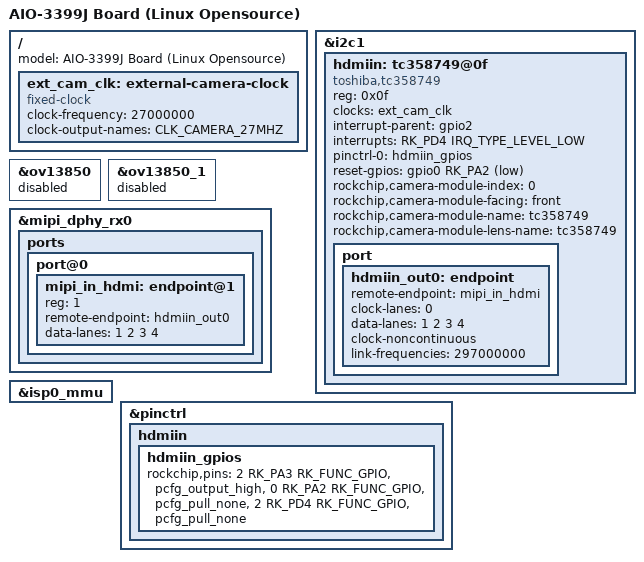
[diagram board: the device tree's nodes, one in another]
/*
 * Copyright (c) 2016 Fuzhou Rockchip Electronics Co., Ltd
 *
 * This file is dual-licensed: you can use it either under the terms
 * of the GPL or the X11 license, at your option. Note that this dual
 * licensing only applies to this file, and not this project as a
 * whole.
 *
 *  a) This file is free software; you can redistribute it and/or
 *     modify it under the terms of the GNU General Public License as
 *     published by the Free Software Foundation; either version 2 of the
 *     License, or (at your option) any later version.
 *
 *     This file is distributed in the hope that it will be useful,
 *     but WITHOUT ANY WARRANTY; without even the implied warranty of
 *     MERCHANTABILITY or FITNESS FOR A PARTICULAR PURPOSE.  See the
 *     GNU General Public License for more details.
 *
 * Or, alternatively,
 *     restriction, including without limitation the rights to use,
 *     copy, modify, merge, publish, distribute, sublicense, and/or
 *     sell copies of the Software, and to permit persons to whom the
 *     Software is furnished to do so, subject to the following
 *     conditions:
 *
 *     The above copyright notice and this permission notice shall be
 *     included in all copies or substantial portions of the Software.
 *
 *     THE SOFTWARE IS PROVIDED "AS IS", WITHOUT WARRANTY OF ANY KIND,
 *     EXPRESS OR IMPLIED, INCLUDING BUT NOT LIMITED TO THE WARRANTIES
 *     OF MERCHANTABILITY, FITNESS FOR A PARTICULAR PURPOSE AND
 *     NONINFRINGEMENT. IN NO EVENT SHALL THE AUTHORS OR COPYRIGHT
 *     HOLDERS BE LIABLE FOR ANY CLAIM, DAMAGES OR OTHER LIABILITY,
 *     WHETHER IN AN ACTION OF CONTRACT, TORT OR OTHERWISE, ARISING
 *     FROM, OUT OF OR IN CONNECTION WITH THE SOFTWARE OR THE USE OR
 *     OTHER DEALINGS IN THE SOFTWARE.
 */

/dts-v1/;

#include "rk3399-firefly-aio.dtsi"

/ {
	model = "AIO-3399J Board (Linux Opensource)";

	ext_cam_clk: external-camera-clock {
		compatible = "fixed-clock";
		clock-frequency = <27000000>;
		clock-output-names = "CLK_CAMERA_27MHZ";
		#clock-cells = <0>;
	};
};

&i2c1 {
	hdmiin: tc358749@0f {
		compatible = "toshiba,tc358749";
		reg = <0x0f>;
		clock-names = "refclk";
		clocks = <&ext_cam_clk>;
		interrupt-parent = <&gpio2>;
		interrupts = <RK_PD4 IRQ_TYPE_LEVEL_LOW>;
		pinctrl-names = "default";
		pinctrl-0 = <&hdmiin_gpios>;
		reset-gpios = <&gpio0 RK_PA2 GPIO_ACTIVE_LOW>;
		rockchip,camera-module-index = <0>;
		rockchip,camera-module-facing = "front";
		rockchip,camera-module-name = "tc358749";
		rockchip,camera-module-lens-name = "tc358749";
		status = "okay";

		port {
			hdmiin_out0: endpoint {
				remote-endpoint = <&mipi_in_hdmi>;
				clock-lanes = <0>;
				data-lanes = <1 2 3 4>;
				clock-noncontinuous;
				link-frequencies =
					/bits/ 64 <297000000>;
			};
		};
	};
};


&ov13850 {
	status = "disabled";
};

&ov13850_1 {
	status = "disabled";
};


&mipi_dphy_rx0 {
	status = "okay";
	ports {
		port@0 {
			mipi_in_hdmi: endpoint@1 {
				reg = <1>;
				remote-endpoint = <&hdmiin_out0>;
				data-lanes = <1 2 3 4>;
			};
		};
	};
};


&isp0_mmu {
	status = "okay";
	/delete-property/ realtek,in1-differential;
};


&pinctrl {
	hdmiin {
		hdmiin_gpios: hdmiin_gpios {
			rockchip,pins =
				<2 RK_PA3 RK_FUNC_GPIO &pcfg_output_high>,
				<0 RK_PA2 RK_FUNC_GPIO &pcfg_pull_none>,
				<2 RK_PD4 RK_FUNC_GPIO &pcfg_pull_none>;
		};
	};
};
